# STM32F107 register map
File version: 1.2
CPU: CM3 r1p1, little endian, no MPU, no FPU, 4 interrupt priority bits
Registers are 32-bit, read-write, reset 0x0 unless marked. A register's access mark holds for its fields unless they carry their own. Offsets are from the block's base; [hi:lo] are bit positions; {n}, {i} and the like mark numbered series; 'fields as' and 'values as' point back to an identical list.

## FSMC — Flexible static memory controller
Base 0xA0000000
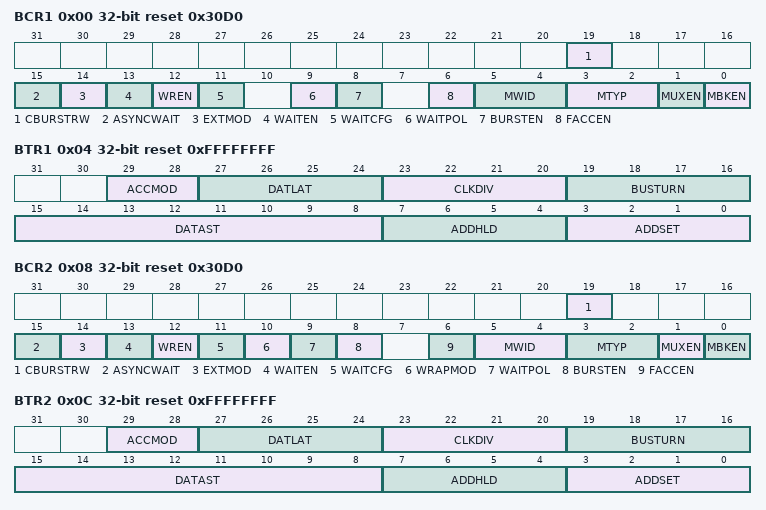
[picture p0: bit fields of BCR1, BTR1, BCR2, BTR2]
0x00 BCR1 reset 0x30D0 — SRAM/NOR-Flash chip-select control register 1
  [19] CBURSTRW, [15] ASYNCWAIT, [14] EXTMOD, [13] WAITEN, [12] WREN, [11] WAITCFG, [9] WAITPOL, [8] BURSTEN, [6] FACCEN, [5:4] MWID, [3:2] MTYP, [1] MUXEN, [0] MBKEN
0x04 BTR1 reset 0xFFFFFFFF — SRAM/NOR-Flash chip-select timing register 1
  [29:28] ACCMOD, [27:24] DATLAT, [23:20] CLKDIV, [19:16] BUSTURN, [15:8] DATAST, [7:4] ADDHLD, [3:0] ADDSET
0x08 BCR2 reset 0x30D0 — SRAM/NOR-Flash chip-select control register 2
  [19] CBURSTRW, [15] ASYNCWAIT, [14] EXTMOD, [13] WAITEN, [12] WREN, [11] WAITCFG, [10] WRAPMOD, [9] WAITPOL, [8] BURSTEN, [6] FACCEN, [5:4] MWID, [3:2] MTYP, [1] MUXEN, [0] MBKEN
0x0C BTR2 reset 0xFFFFFFFF — SRAM/NOR-Flash chip-select timing register 2
  fields as BTR1
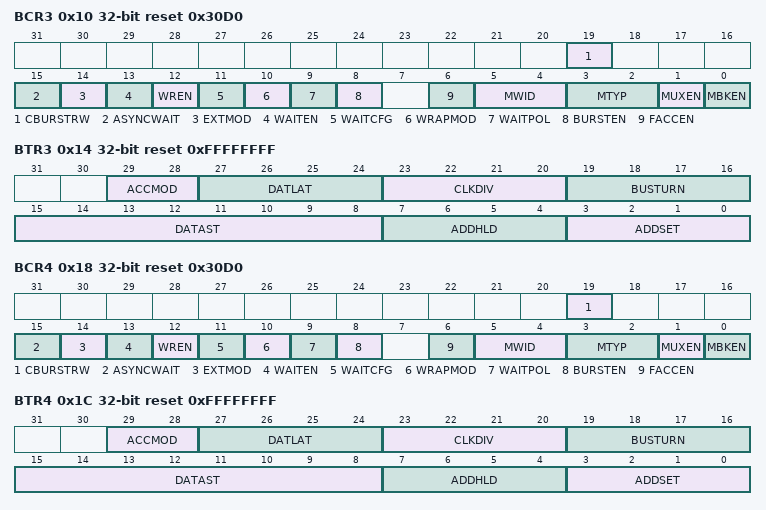
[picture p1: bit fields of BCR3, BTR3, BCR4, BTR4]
0x10 BCR3 reset 0x30D0 — SRAM/NOR-Flash chip-select control register 3
  fields as BCR2
0x14 BTR3 reset 0xFFFFFFFF — SRAM/NOR-Flash chip-select timing register 3
  fields as BTR1
0x18 BCR4 reset 0x30D0 — SRAM/NOR-Flash chip-select control register 4
  fields as BCR2
0x1C BTR4 reset 0xFFFFFFFF — SRAM/NOR-Flash chip-select timing register 4
  fields as BTR1
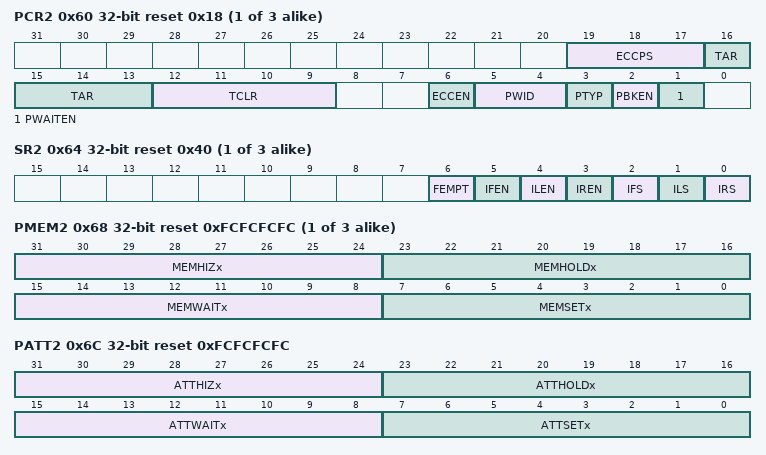
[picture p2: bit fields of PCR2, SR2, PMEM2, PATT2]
{0x20+0x20*i} PCR{i} reset 0x18 (i=2..4) — PC Card/NAND Flash control register {i}
  [19:17] ECCPS, [16:13] TAR, [12:9] TCLR, [6] ECCEN, [5:4] PWID, [3] PTYP, [2] PBKEN, [1] PWAITEN
{0x24+0x20*i} SR{i} access per field reset 0x40 (i=2..4) — FIFO status and interrupt register {i}
  [6] FEMPT ro, [5] IFEN rw, [4] ILEN rw, [3] IREN rw, [2] IFS rw, [1] ILS rw, [0] IRS rw
{0x28+0x20*i} PMEM{i} reset 0xFCFCFCFC (i=2..4) — Common memory space timing register {i}
  [31:24] MEMHIZx, [23:16] MEMHOLDx, [15:8] MEMWAITx, [7:0] MEMSETx
0x6C PATT2 reset 0xFCFCFCFC — Attribute memory space timing register 2
  [31:24] ATTHIZx — Attribute memory x databus HiZ time
  [23:16] ATTHOLDx — Attribute memory x hold time
  [15:8] ATTWAITx — Attribute memory x wait time
  [7:0] ATTSETx — Attribute memory x setup time
0x74 ECCR2 ro — ECC result register 2
  [31:0] ECCx — ECC result
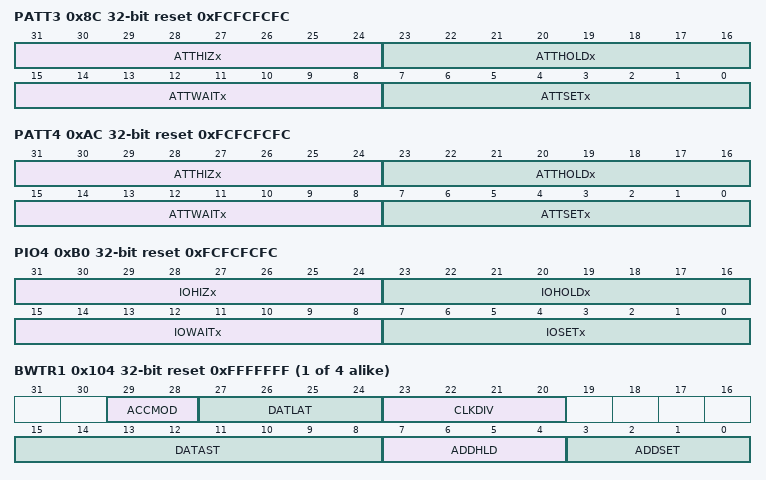
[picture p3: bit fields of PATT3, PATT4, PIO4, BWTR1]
0x8C PATT3 reset 0xFCFCFCFC — Attribute memory space timing register 3
  [31:24] ATTHIZx, [23:16] ATTHOLDx, [15:8] ATTWAITx, [7:0] ATTSETx
0x94 ECCR3 ro — ECC result register 3
  [31:0] ECCx
0xAC PATT4 reset 0xFCFCFCFC — Attribute memory space timing register 4
  [31:24] ATTHIZx, [23:16] ATTHOLDx, [15:8] ATTWAITx, [7:0] ATTSETx
0xB0 PIO4 reset 0xFCFCFCFC — I/O space timing register 4
  [31:24] IOHIZx, [23:16] IOHOLDx, [15:8] IOWAITx, [7:0] IOSETx
{0xFC+8i} BWTR{i} reset 0xFFFFFFF (i=1..4) — SRAM/NOR-Flash write timing registers {i}
  [29:28] ACCMOD, [27:24] DATLAT, [23:20] CLKDIV, [15:8] DATAST, [7:4] ADDHLD, [3:0] ADDSET

## TIM11 — General purpose timer
Base 0x40015400
Same registers: TIM10 0x40015000
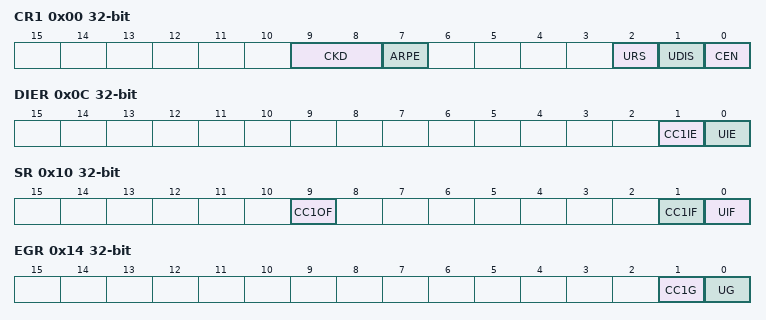
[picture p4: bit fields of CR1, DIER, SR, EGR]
0x00 CR1 — control register 1
  [9:8] CKD — Clock division
  [7] ARPE — Auto-reload preload enable
  [2] URS — Update request source
  [1] UDIS — Update disable
  [0] CEN — Counter enable
0x0C DIER — DMA/Interrupt enable register
  [1] CC1IE — Capture/Compare 1 interrupt enable
  [0] UIE — Update interrupt enable
0x10 SR — status register
  [9] CC1OF — Capture/Compare 1 overcapture flag
  [1] CC1IF — Capture/compare 1 interrupt flag
  [0] UIF — Update interrupt flag
0x14 EGR wo — event generation register
  [1] CC1G — Capture/compare 1 generation
  [0] UG — Update generation
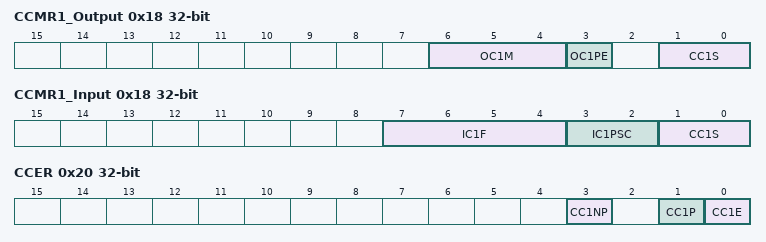
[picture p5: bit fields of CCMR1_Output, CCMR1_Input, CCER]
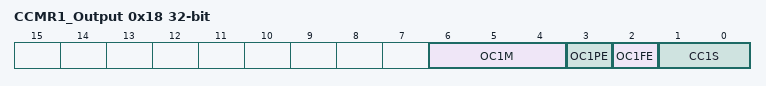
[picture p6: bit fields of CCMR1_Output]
0x18 CCMR1_Output — capture/compare mode register (output mode)
  [6:4] OC1M — Output Compare 1 mode
  [3] OC1PE — Output Compare 1 preload enable
  [1:0] CC1S — Capture/Compare 1 selection
0x18 CCMR1_Input (alternate view of CCMR1_Output) — capture/compare mode register (input mode)
  [7:4] IC1F — Input capture 1 filter
  [3:2] IC1PSC — Input capture 1 prescaler
  [1:0] CC1S — Capture/Compare 1 selection
0x20 CCER — capture/compare enable register
  [3] CC1NP — Capture/Compare 1 output Polarity
  [1] CC1P — Capture/Compare 1 output Polarity
  [0] CC1E — Capture/Compare 1 output enable
0x24 CNT — counter
  [15:0] CNT — counter value
0x28 PSC — prescaler
  [15:0] PSC — Prescaler value
0x2C ARR — auto-reload register
  [15:0] ARR — Auto-reload value
0x34 CCR1 — capture/compare register 1
  [15:0] CCR1 — Capture/Compare 1 value

## TIM13 — General purpose timer
Base 0x40001C00
Same registers: TIM14 0x40002000
Registers as TIM11; these are added or differ:
0x18 CCMR1_Output — capture/compare mode register (output mode)
  [6:4] OC1M — Output Compare 1 mode
  [3] OC1PE — Output Compare 1 preload enable
  [2] OC1FE — Output compare 1 fast enable
  [1:0] CC1S — Capture/Compare 1 selection
